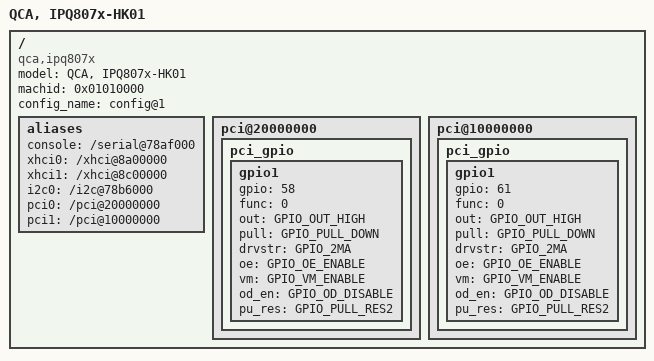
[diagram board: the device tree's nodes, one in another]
/*
 * Copyright (c) 2016, The Linux Foundation. All rights reserved.
 *
 * This program is free software; you can redistribute it and/or modify
 * it under the terms of the GNU General Public License version 2 and
 * only version 2 as published by the Free Software Foundation.
 *
 * This program is distributed in the hope that it will be useful,
 * but WITHOUT ANY WARRANTY; without even the implied warranty of
 * MERCHANTABILITY or FITNESS FOR A PARTICULAR PURPOSE.  See the
 * GNU General Public License for more details.
 */

/dts-v1/;
#include "ipq807x-soc.dtsi"
#include <dt-bindings/qcom/gpio-ipq807x.h>
/ {
	model ="QCA, IPQ807x-HK01";
	compatible = "qca,ipq807x", "qca,ipq807x-hk01";
	machid = <0x01010000>;
	config_name = "config@1";

	aliases {
		console = "/serial@78af000";
		xhci0 = "/xhci@8a00000";
		xhci1 = "/xhci@8c00000";
		i2c0 = "/i2c@78b6000";
		pci0 = "/pci@20000000";
		pci1 = "/pci@10000000";
	};
	pci@20000000 {
		pci_gpio {
			gpio1 {
				gpio = <58>;
				func = <0>;
				out = <GPIO_OUT_HIGH>;
				pull = <GPIO_PULL_DOWN>;
				drvstr = <GPIO_2MA>;
				oe = <GPIO_OE_ENABLE>;
				vm = <GPIO_VM_ENABLE>;
				od_en = <GPIO_OD_DISABLE>;
				pu_res = <GPIO_PULL_RES2>;
			};

		};
	};

	pci@10000000 {
		pci_gpio {
			gpio1 {
				gpio = <61>;
				func = <0>;
				out = <GPIO_OUT_HIGH>;
				pull = <GPIO_PULL_DOWN>;
				drvstr = <GPIO_2MA>;
				oe = <GPIO_OE_ENABLE>;
				vm = <GPIO_VM_ENABLE>;
				od_en = <GPIO_OD_DISABLE>;
				pu_res = <GPIO_PULL_RES2>;
			};

		};
	};
};

